VERSION ""

NS_ :

BS_:

BU_:

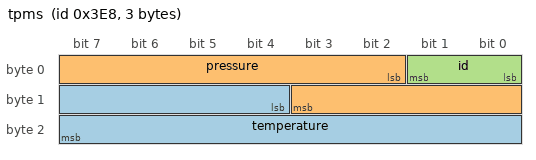
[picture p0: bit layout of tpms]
BO_ 1000 tpms: 3 Vector__XXX
 SG_ temperature : 12|12@1+ (0.1,0) [0|409.5] "C" Vector__XXX
 SG_ pressure : 2|10@1+ (0.1,0) [0|102.3] "psi" Vector__XXX
 SG_ id : 0|2@1+ (1,0) [0|15] "-" Vector__XXX

BA_DEF_ BO_  "GenMsgBackgroundColor" STRING ;
BA_DEF_ BO_  "GenMsgForegroundColor" STRING ;
BA_DEF_ BO_  "filterlabeling" INT 0 0;
BA_DEF_DEF_  "GenMsgBackgroundColor" "#ffffff";
BA_DEF_DEF_  "GenMsgForegroundColor" "#000000";
BA_DEF_DEF_  "filterlabeling" 1;
